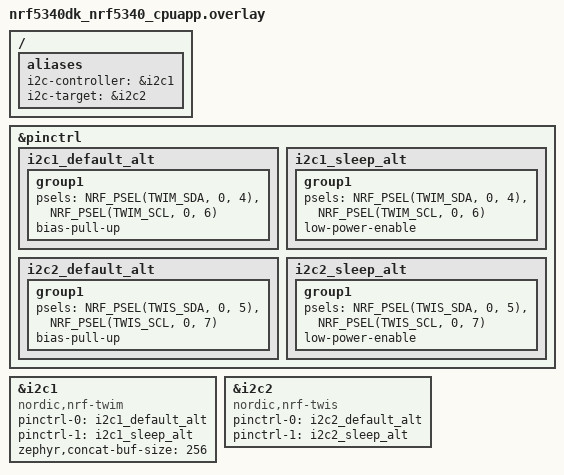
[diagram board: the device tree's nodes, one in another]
/*
 * Copyright (c) 2026 Nordic Semiconductor ASA
 *
 * SPDX-License-Identifier: LicenseRef-Nordic-5-Clause
 */

/*
 * SDA = P0.4 and P0.5
 * SCL = P0.6 and P0.7
 */

/ {
	aliases {
		i2c-controller = &i2c1;
		i2c-target = &i2c2;
	};
};

&pinctrl {
	i2c1_default_alt: i2c1_default_alt {
		group1 {
			psels = <NRF_PSEL(TWIM_SDA, 0, 4)>,
				<NRF_PSEL(TWIM_SCL, 0, 6)>;
			bias-pull-up;
		};
	};

	i2c1_sleep_alt: i2c1_sleep_alt {
		group1 {
			psels = <NRF_PSEL(TWIM_SDA, 0, 4)>,
				<NRF_PSEL(TWIM_SCL, 0, 6)>;
			low-power-enable;
		};
	};

	i2c2_default_alt: i2c2_default_alt {
		group1 {
			psels = <NRF_PSEL(TWIS_SDA, 0, 5)>,
				<NRF_PSEL(TWIS_SCL, 0, 7)>;
			bias-pull-up;
		};
	};

	i2c2_sleep_alt: i2c2_sleep_alt {
		group1 {
			psels = <NRF_PSEL(TWIS_SDA, 0, 5)>,
				<NRF_PSEL(TWIS_SCL, 0, 7)>;
			low-power-enable;
		};
	};
};

&i2c1 {
	compatible = "nordic,nrf-twim";
	pinctrl-0 = <&i2c1_default_alt>;
	pinctrl-1 = <&i2c1_sleep_alt>;
	pinctrl-names = "default", "sleep";
	zephyr,concat-buf-size = <256>;
	status = "okay";
};

&i2c2 {
	compatible = "nordic,nrf-twis";
	pinctrl-0 = <&i2c2_default_alt>;
	pinctrl-1 = <&i2c2_sleep_alt>;
	pinctrl-names = "default", "sleep";
	status = "okay";
};
